# STM32N645 register map
File version: 1.0
CPU: CM55 r0p1, little endian, no MPU, FPU, vendor SysTick, 8 interrupt priority bits
Registers are 32-bit, read-write, reset 0x0 unless marked. A register's access mark holds for its fields unless they carry their own. Offsets are from the block's base; [hi:lo] are bit positions; {n}, {i} and the like mark numbered series.

## SDMMC1 — Secure digital input/output MultiMediaCard interface
Base 0x48027000
Same registers: SDMMC2 0x48026800, SDMMC2_S 0x58026800, SDMMC1_S 0x58027000
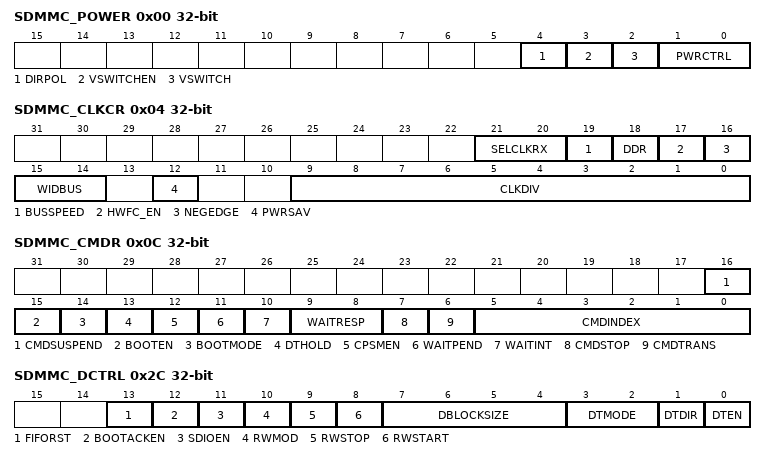
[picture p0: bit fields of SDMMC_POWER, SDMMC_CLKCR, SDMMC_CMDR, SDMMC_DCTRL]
0x00 SDMMC_POWER — SDMMC power control register
  [4] DIRPOL — Data and command direction signals polarity selection
    0=Voltage transceiver IOs driven as output when direction signal is low; 1=Voltage transceiver IOs driven as output when direction signal is high
  [3] VSWITCHEN — Voltage switch procedure enable
    0=SDMMC_CK clock kept unchanged after successfully received command response; 1=SDMMC_CK clock stopped after successfully received command response
  [2] VSWITCH — Voltage switch sequence start
    0=Voltage switch sequence not started and not active; 1=Voltage switch sequence started or active
  [1:0] PWRCTRL — SDMMC state control bits
    0=After reset, Reset: the SDMMC is disabled and the clock to the Card is stopped, SDMMC_D[7:0], and SDMMC_CMD are HiZ and SDMMC_CK is driven low; 2=Power-cycle, the SDMMC is disabled and the clock to the card is stopped, SDMMC_D[7:0], SDMMC_CMD and SDMMC_CK are driven low; 3=Power-on: the card is clocked, The first 74 SDMMC_CK cycles the SDMMC is still disabled. After the 74 cycles the SDMMC is enabled and the SDMMC_D[7:0], SDMMC_CMD and SDMMC_CK are controlled according the SDMMC operation.
0x04 SDMMC_CLKCR — SDMMC clock control register
  [21:20] SELCLKRX — Receive clock selection
    0=sdmmc_io_in_ck selected as receive clock; 1=SDMMC_CKIN feedback clock selected as receive clock; 2=sdmmc_fb_ck tuned feedback clock selected as receive clock
  [19] BUSSPEED — Bus speed for selection of SDMMC operating modes
    0=DS, HS, SDR12, SDR25, Legacy compatible, High speed SDR, High speed DDR bus speed mode selected; 1=SDR50, DDR50, SDR104, HS200 bus speed mode selected
  [18] DDR — Data rate signaling selection
    0=SDR Single data rate signaling; 1=DDR double data rate signaling
  [17] HWFC_EN — Hardware flow control enable
    0=Hardware flow control is disabled; 1=Hardware flow control is enabled
  [16] NEGEDGE — SDMMC_CK dephasing selection bit for data and command
    0=When clock division >1 (CLKDIV > 0) and DDR = 0:; 1=When clock division >1 (CLKDIV > 0) and DDR = 0:
  [15:14] WIDBUS — Wide bus mode enable bit
    0=Default 1-bit wide bus mode: SDMMC_D0 used (Does not support DDR); 1=4-bit wide bus mode: SDMMC_D[3:0] used; 2=8-bit wide bus mode: SDMMC_D[7:0] used
  [12] PWRSAV — Power saving configuration bit
    0=SDMMC_CK clock is always enabled; 1=SDMMC_CK is only enabled when the bus is active
  [9:0] CLKDIV — Clock divide factor
    0=SDMMC_CK frequency = sdmmc_ker_ck / 1 (Does not support DDR); 1=SDMMC_CK frequency = sdmmc_ker_ck / 2; 2=SDMMC_CK frequency = sdmmc_ker_ck / 4; 128=SDMMC_CK frequency = sdmmc_ker_ck / 256; 0x3FF=SDMMC_CK frequency = sdmmc_ker_ck / 2046
0x08 SDMMC_ARGR — SDMMC argument register
  [31:0] CMDARG — Command argument
0x0C SDMMC_CMDR — SDMMC command register
  [16] CMDSUSPEND — The CPSM treats the command as a Suspend or Resume command and signals interrupt period start/end
  [15] BOOTEN — Enable boot mode procedure
    0=Boot mode procedure disabled; 1=Boot mode procedure enabled
  [14] BOOTMODE — Select the boot mode procedure to be used
    0=Normal boot mode procedure selected; 1=Alternative boot mode procedure selected
  [13] DTHOLD — Hold new data block transmission and reception in the DPSM
  [12] CPSMEN — Command path state machine (CPSM) enable bit
  [11] WAITPEND — CPSM waits for end of data transfer (CmdPend internal signal) from DPSM
  [10] WAITINT — CPSM waits for interrupt request
  [9:8] WAITRESP — Wait for response bits
    0=No response, expect CMDSENT flag; 1=Short response, expect CMDREND or CCRCFAIL flag; 2=Short response, expect CMDREND flag (No CRC); 3=Long response, expect CMDREND or CCRCFAIL flag
  [7] CMDSTOP — The CPSM treats the command as a Stop Transmission command and signals abort to the DPSM
  [6] CMDTRANS — The CPSM treats the command as a data transfer command, stops the interrupt period, and signals DataEnable to the DPSM
  [5:0] CMDINDEX — Command index
0x10 SDMMC_RESPCMDR ro — SDMMC command response register
  [5:0] RESPCMD — Response command index
{0x10+4i} SDMMC_RESP{i}R ro (i=1..4) — SDMMC response {i} register
  [31:0] CARDSTATUS — Card status according table below
0x24 SDMMC_DTIMER — SDMMC data timer register
  [31:0] DATATIME — Data and R1b busy timeout period
0x28 SDMMC_DLENR — SDMMC data length register
  [24:0] DATALENGTH — Data length value
0x2C SDMMC_DCTRL — SDMMC data control register
  [13] FIFORST — FIFO reset, flushes any remaining data
    0=FIFO not affected; 1=Flush any remaining data and reset the FIFO pointers. This bit is automatically cleared to 0 by hardware when DPSM gets inactive (DPSMACT = 0).
  [12] BOOTACKEN — Enable the reception of the boot acknowledgment
    0=Boot acknowledgment disabled, not expected to be received; 1=Boot acknowledgment enabled, expected to be received
  [11] SDIOEN — SD I/O interrupt enable functions
  [10] RWMOD — Read Wait mode
    0=Read Wait control using SDMMC_D2; 1=Read Wait control stopping SDMMC_CK
  [9] RWSTOP — Read Wait stop
    0=No Read Wait stop; 1=Enable for Read Wait stop when DPSM is in the R_W state
  [8] RWSTART — Read Wait start
  [7:4] DBLOCKSIZE — Data block size
    0=Block length = 2 less than sup>0 less than /sup> = 1 byte; 1=Block length = 2 less than sup>1 less than /sup> = 2 bytes; 2=Block length = 2 less than sup>2 less than /sup>= 4 bytes; 3=Block length = 2 less than sup>3 less than /sup> = 8 bytes; 4=Block length = 2 less than sup>4 less than /sup> = 16 bytes; 5=Block length = 2 less than sup>5 less than /sup> = 32 bytes; 6=Block length = 2 less than sup>6 less than /sup> = 64 bytes; 7=Block length = 2 less than sup>7 less than /sup> = 128 bytes; 8=Block length = 2 less than sup>8 less than /sup> = 256 bytes; 9=Block length = 2 less than sup>9 less than /sup> = 512 bytes; 10=Block length = 2 less than sup>10 less than /sup> = 1024 bytes; 11=Block length = 2 less than sup>11 less than /sup> = 2048 bytes; 12=Block length = 2 less than sup>12 less than /sup> = 4096 bytes; 13=Block length = 2 less than sup>13 less than /sup> = 8192 bytes; 14=Block length = 2 less than sup>14 less than /sup> = 16384 bytes
  [3:2] DTMODE — Data transfer mode selection
    0=Block data transfer ending on block count; 1=SDIO multibyte data transfer; 2=e MMC Stream data transfer. (WIDBUS must select 1-bit wide bus mode); 3=Block data transfer ending with STOP_TRANSMISSION command (not to be used with DTEN initiated data transfers)
  [1] DTDIR — Data transfer direction selection
    0=From host to card; 1=From card to host
  [0] DTEN — Data transfer enable bit
    0=Do not start data transfer without CPSM data transfer command; 1=Start data transfer without CPSM data transfer command
0x30 SDMMC_DCNTR ro — SDMMC data counter register
  [24:0] DATACOUNT — Data count value
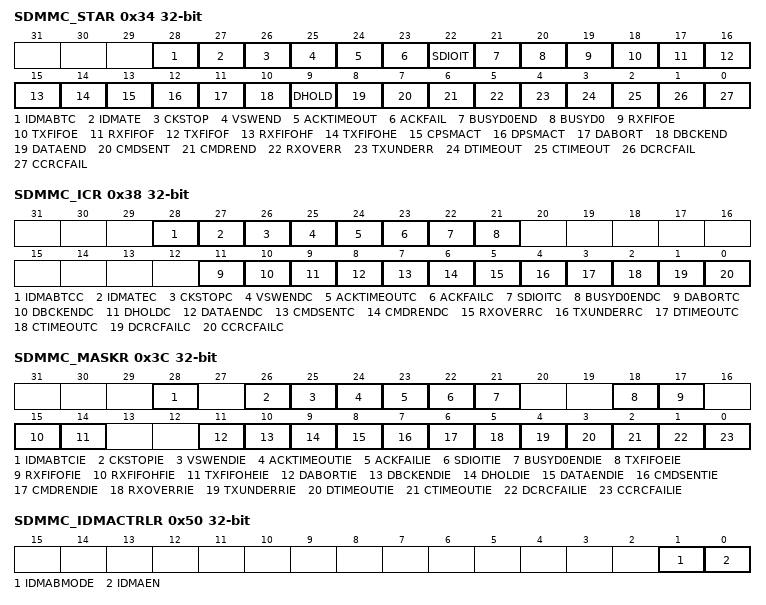
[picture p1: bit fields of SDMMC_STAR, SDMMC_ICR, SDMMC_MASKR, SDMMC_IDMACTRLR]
0x34 SDMMC_STAR ro — SDMMC status register
  [28] IDMABTC — IDMA buffer transfer complete
  [27] IDMATE — IDMA transfer error
  [26] CKSTOP — SDMMC_CK stopped in Voltage switch procedure
  [25] VSWEND — Voltage switch critical timing section completion
  [24] ACKTIMEOUT — Boot acknowledgment timeout
  [23] ACKFAIL — Boot acknowledgment received (boot acknowledgment check fail)
  [22] SDIOIT — SDIO interrupt received
  [21] BUSYD0END — end of SDMMC_D0 Busy following a CMD response detected
    0=card SDMMC_D0 signal does NOT signal change from busy to not busy; 1=card SDMMC_D0 signal changed from busy to NOT busy
  [20] BUSYD0 — Inverted value of SDMMC_D0 line (Busy), sampled at the end of a CMD response and a second time 2 SDMMC_CK cycles after the CMD response
    0=card signals not busy on SDMMC_D0; 1=card signals busy on SDMMC_D0
  [19] RXFIFOE — Receive FIFO empty
  [18] TXFIFOE — Transmit FIFO empty
  [17] RXFIFOF — Receive FIFO full
  [16] TXFIFOF — Transmit FIFO full
  [15] RXFIFOHF — Receive FIFO half full
  [14] TXFIFOHE — Transmit FIFO half empty
  [13] CPSMACT — Command path state machine active, i.e. not in Idle state
  [12] DPSMACT — Data path state machine active, i.e. not in Idle state
  [11] DABORT — Data transfer aborted by CMD12
  [10] DBCKEND — Data block sent/received
  [9] DHOLD — Data transfer Hold
  [8] DATAEND — Data transfer ended correctly
  [7] CMDSENT — Command sent (no response required)
  [6] CMDREND — Command response received (CRC check passed, or no CRC)
  [5] RXOVERR — Received FIFO overrun error (masked by hardware when IDMA is enabled)
  [4] TXUNDERR — Transmit FIFO underrun error (masked by hardware when IDMA is enabled)
  [3] DTIMEOUT — Data timeout
  [2] CTIMEOUT — Command response timeout
  [1] DCRCFAIL — Data block sent/received (CRC check failed)
  [0] CCRCFAIL — Command response received (CRC check failed)
0x38 SDMMC_ICR — SDMMC interrupt clear register
  [28] IDMABTCC — IDMA buffer transfer complete clear bit
    0=IDMABTC not cleared; 1=IDMABTC cleared
  [27] IDMATEC — IDMA transfer error clear bit
    0=IDMATE not cleared; 1=IDMATE cleared
  [26] CKSTOPC — CKSTOP flag clear bit
    0=CKSTOP not cleared; 1=CKSTOP cleared
  [25] VSWENDC — VSWEND flag clear bit
    0=VSWEND not cleared; 1=VSWEND cleared
  [24] ACKTIMEOUTC — ACKTIMEOUT flag clear bit
    0=ACKTIMEOUT not cleared; 1=ACKTIMEOUT cleared
  [23] ACKFAILC — ACKFAIL flag clear bit
    0=ACKFAIL not cleared; 1=ACKFAIL cleared
  [22] SDIOITC — SDIOIT flag clear bit
    0=SDIOIT not cleared; 1=SDIOIT cleared
  [21] BUSYD0ENDC — BUSYD0END flag clear bit
    0=BUSYD0END not cleared; 1=BUSYD0END cleared
  [11] DABORTC — DABORT flag clear bit
    0=DABORT not cleared; 1=DABORT cleared
  [10] DBCKENDC — DBCKEND flag clear bit
    0=DBCKEND not cleared; 1=DBCKEND cleared
  [9] DHOLDC — DHOLD flag clear bit
    0=DHOLD not cleared; 1=DHOLD cleared
  [8] DATAENDC — DATAEND flag clear bit
    0=DATAEND not cleared; 1=DATAEND cleared
  [7] CMDSENTC — CMDSENT flag clear bit
    0=CMDSENT not cleared; 1=CMDSENT cleared
  [6] CMDRENDC — CMDREND flag clear bit
    0=CMDREND not cleared; 1=CMDREND cleared
  [5] RXOVERRC — RXOVERR flag clear bit
    0=RXOVERR not cleared; 1=RXOVERR cleared
  [4] TXUNDERRC — TXUNDERR flag clear bit
    0=TXUNDERR not cleared; 1=TXUNDERR cleared
  [3] DTIMEOUTC — DTIMEOUT flag clear bit
    0=DTIMEOUT not cleared; 1=DTIMEOUT cleared
  [2] CTIMEOUTC — CTIMEOUT flag clear bit
    0=CTIMEOUT not cleared; 1=CTIMEOUT cleared
  [1] DCRCFAILC — DCRCFAIL flag clear bit
    0=DCRCFAIL not cleared; 1=DCRCFAIL cleared
  [0] CCRCFAILC — CCRCFAIL flag clear bit
    0=CCRCFAIL not cleared; 1=CCRCFAIL cleared
0x3C SDMMC_MASKR — SDMMC mask register
  [28] IDMABTCIE — IDMA buffer transfer complete interrupt enable
    0=IDMA buffer transfer complete interrupt disabled; 1=IDMA buffer transfer complete interrupt enabled
  [26] CKSTOPIE — Voltage Switch clock stopped interrupt enable
    0=Voltage Switch clock stopped interrupt disabled; 1=Voltage Switch clock stopped interrupt enabled
  [25] VSWENDIE — Voltage switch critical timing section completion interrupt enable
    0=Voltage switch critical timing section completion interrupt disabled; 1=Voltage switch critical timing section completion interrupt enabled
  [24] ACKTIMEOUTIE — Acknowledgment timeout interrupt enable
    0=Acknowledgment timeout interrupt disabled; 1=Acknowledgment timeout interrupt enabled
  [23] ACKFAILIE — Acknowledgment Fail interrupt enable
    0=Acknowledgment Fail interrupt disabled; 1=Acknowledgment Fail interrupt enabled
  [22] SDIOITIE — SDIO mode interrupt received interrupt enable
    0=SDIO Mode interrupt received interrupt disabled; 1=SDIO Mode interrupt received interrupt enabled
  [21] BUSYD0ENDIE — BUSYD0END interrupt enable
    0=BUSYD0END interrupt disabled; 1=BUSYD0END interrupt enabled
  [18] TXFIFOEIE — Tx FIFO empty interrupt enable
    0=Tx FIFO empty interrupt disabled; 1=Tx FIFO empty interrupt enabled
  [17] RXFIFOFIE — Rx FIFO full interrupt enable
    0=Rx FIFO full interrupt disabled; 1=Rx FIFO full interrupt enabled
  [15] RXFIFOHFIE — Rx FIFO half full interrupt enable
    0=Rx FIFO half full interrupt disabled; 1=Rx FIFO half full interrupt enabled
  [14] TXFIFOHEIE — Tx FIFO half empty interrupt enable
    0=Tx FIFO half empty interrupt disabled; 1=Tx FIFO half empty interrupt enabled
  [11] DABORTIE — Data transfer aborted interrupt enable
    0=Data transfer abort interrupt disabled; 1=Data transfer abort interrupt enabled
  [10] DBCKENDIE — Data block end interrupt enable
    0=Data block end interrupt disabled; 1=Data block end interrupt enabled
  [9] DHOLDIE — Data hold interrupt enable
    0=Data hold interrupt disabled; 1=Data hold interrupt enabled
  [8] DATAENDIE — Data end interrupt enable
    0=Data end interrupt disabled; 1=Data end interrupt enabled
  [7] CMDSENTIE — Command sent interrupt enable
    0=Command sent interrupt disabled; 1=Command sent interrupt enabled
  [6] CMDRENDIE — Command response received interrupt enable
    0=Command response received interrupt disabled; 1=command Response received interrupt enabled
  [5] RXOVERRIE — Rx FIFO overrun error interrupt enable
    0=Rx FIFO overrun error interrupt disabled; 1=Rx FIFO overrun error interrupt enabled
  [4] TXUNDERRIE — Tx FIFO underrun error interrupt enable
    0=Tx FIFO underrun error interrupt disabled; 1=Tx FIFO underrun error interrupt enabled
  [3] DTIMEOUTIE — Data timeout interrupt enable
    0=Data timeout interrupt disabled; 1=Data timeout interrupt enabled
  [2] CTIMEOUTIE — Command timeout interrupt enable
    0=Command timeout interrupt disabled; 1=Command timeout interrupt enabled
  [1] DCRCFAILIE — Data CRC fail interrupt enable
    0=Data CRC fail interrupt disabled; 1=Data CRC fail interrupt enabled
  [0] CCRCFAILIE — Command CRC fail interrupt enable
    0=Command CRC fail interrupt disabled; 1=Command CRC fail interrupt enabled
0x40 SDMMC_ACKTIMER — SDMMC acknowledgment timer register
  [24:0] ACKTIME — Boot acknowledgment timeout period
0x44 SDMMC_FIFOTHRR — SDMMC data FIFO threshold register
  [3:0] THR — FIFO threshold
    0=threshold = 0 byte (no threshold)
0x50 SDMMC_IDMACTRLR — SDMMC DMA control register
  [1] IDMABMODE — Buffer mode selection
    0=Single buffer mode; 1=Linked list mode
  [0] IDMAEN — IDMA enable
    0=IDMA disabled; 1=IDMA enabled
0x54 SDMMC_IDMABSIZER — SDMMC IDMA buffer size register
  [16:6] IDMABNDT — Number of bytes per buffer
0x58 SDMMC_IDMABASER — SDMMC IDMA buffer base address register
  [31:0] IDMABASE — Buffer memory base address bits [31:2], must be word aligned (bit [1:0] are always 0 and read only)
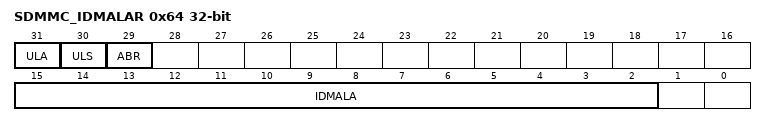
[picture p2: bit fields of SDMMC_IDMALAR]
0x64 SDMMC_IDMALAR — SDMMC IDMA linked list address register
  [31] ULA — Update SDMMC_IDMALAR from linked list when in linked list mode (SDMMC_IDMACTRLR.IDMABMODE select linked list mode)
    0=SDMMC_IDMALAR is not to be updated, last linked list item; 1=SDMMC_IDMALAR is to be updated from linked list table
  [30] ULS — Update SDMMC_IDMABSIZE from the next linked list when in linked list mode (SDMMC_IDMACTRLR.IDMABMODE select linked list mode and ULA = 1)
    0=SDMMC_IDMABSIZER is not to be updated from next linked list table; 1=SDMMC_IDMABSIZER is to be updated from next linked list table
  [29] ABR — Acknowledge linked list buffer ready
    0=Loaded linked list buffer is not ready (this causes a linked list IDMA transfer error to be generated); 1=Loaded linked list buffer ready acknowledge. Linked list buffer data are transfered by IDMA.
  [15:2] IDMALA — Word aligned linked list item address offset
0x68 SDMMC_IDMABAR — SDMMC IDMA linked list memory base register
  [31:2] IDMABA — Word aligned Linked list memory base address
{0x80+4i} SDMMC_FIFOR{i} (i=0..15) — SDMMC data FIFO registers {i}
  [31:0] FIFODATA — Receive and transmit FIFO data
